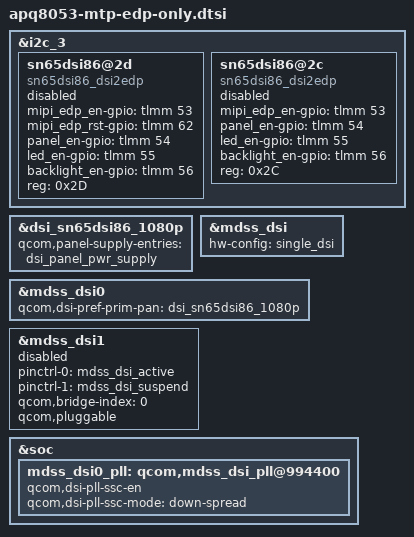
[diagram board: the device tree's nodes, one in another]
 /* Copyright (c) 2015-2016, The Linux Foundation. All rights reserved.
 *
 * This program is free software; you can redistribute it and/or modify
 * it under the terms of the GNU General Public License version 2 and
 * only version 2 as published by the Free Software Foundation.
 *
 * This program is distributed in the hope that it will be useful,
 * but WITHOUT ANY WARRANTY; without even the implied warranty of
 * MERCHANTABILITY or FITNESS FOR A PARTICULAR PURPOSE.  See the
 * GNU General Public License for more details.
 */
//Leo Guo add this file to support all panel in one image
#include "dsi-sn65dsi86-1080p.dtsi"

&i2c_3 {
	sn65dsi86@2d {
			compatible = "sn65dsi86_dsi2edp";
			status="disabled";
			mipi_edp_en-gpio = <&tlmm 53 0>;
			mipi_edp_rst-gpio =<&tlmm 62 0>;
			panel_en-gpio = <&tlmm 54 0>;
			led_en-gpio = <&tlmm 55 0>;
			backlight_en-gpio = <&tlmm 56 0>;
			reg = <0x2D>;
	};

	sn65dsi86@2c {
			compatible = "sn65dsi86_dsi2edp";
			status="disabled";
			mipi_edp_en-gpio = <&tlmm 53 0>;
			panel_en-gpio = <&tlmm 54 0>;
			led_en-gpio = <&tlmm 55 0>;
			backlight_en-gpio = <&tlmm 56 0>;
			reg = <0x2C>;
	};
};

&dsi_sn65dsi86_1080p {
	qcom,panel-supply-entries = <&dsi_panel_pwr_supply>;
};
&mdss_dsi {
	hw-config = "single_dsi";
};

&mdss_dsi0 {
	status = "okay";
	qcom,dsi-pref-prim-pan = <&dsi_sn65dsi86_1080p>;
	pinctrl-names = "mdss_default", "mdss_sleep";
};

&mdss_dsi1 {
	status = "disabled";
	pinctrl-names = "mdss_default", "mdss_sleep";
	pinctrl-0 = <&mdss_dsi_active>;
	pinctrl-1 = <&mdss_dsi_suspend>;
	qcom,bridge-index = <0>;
	qcom,pluggable;
};

&soc {
	mdss_dsi0_pll: qcom,mdss_dsi_pll@994400 {
		qcom,dsi-pll-ssc-en;
		qcom,dsi-pll-ssc-mode = "down-spread";
	};
};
